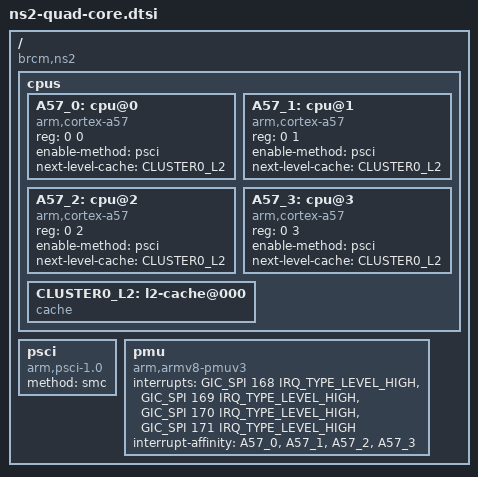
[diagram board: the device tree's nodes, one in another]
/*
 *  BSD LICENSE
 *
 *  Copyright (c) 2017 Broadcom.  All rights reserved.
 *
 *  Redistribution and use in source and binary forms, with or without
 *  modification, are permitted provided that the following conditions
 *  are met:
 *
 *    * Redistributions of source code must retain the above copyright
 *      notice, this list of conditions and the following disclaimer.
 *    * Redistributions in binary form must reproduce the above copyright
 *      notice, this list of conditions and the following disclaimer in
 *      the documentation and/or other materials provided with the
 *      distribution.
 *    * Neither the name of Broadcom Corporation nor the names of its
 *      contributors may be used to endorse or promote products derived
 *      from this software without specific prior written permission.
 *
 *  THIS SOFTWARE IS PROVIDED BY THE COPYRIGHT HOLDERS AND CONTRIBUTORS
 *  "AS IS" AND ANY EXPRESS OR IMPLIED WARRANTIES, INCLUDING, BUT NOT
 *  LIMITED TO, THE IMPLIED WARRANTIES OF MERCHANTABILITY AND FITNESS FOR
 *  A PARTICULAR PURPOSE ARE DISCLAIMED. IN NO EVENT SHALL THE COPYRIGHT
 *  OWNER OR CONTRIBUTORS BE LIABLE FOR ANY DIRECT, INDIRECT, INCIDENTAL,
 *  SPECIAL, EXEMPLARY, OR CONSEQUENTIAL DAMAGES (INCLUDING, BUT NOT
 *  LIMITED TO, PROCUREMENT OF SUBSTITUTE GOODS OR SERVICES; LOSS OF USE,
 *  DATA, OR PROFITS; OR BUSINESS INTERRUPTION) HOWEVER CAUSED AND ON ANY
 *  THEORY OF LIABILITY, WHETHER IN CONTRACT, STRICT LIABILITY, OR TORT
 *  (INCLUDING NEGLIGENCE OR OTHERWISE) ARISING IN ANY WAY OUT OF THE USE
 * OF THIS SOFTWARE, EVEN IF ADVISED OF THE POSSIBILITY OF SUCH DAMAGE.
 */
#include "ns2.dtsi"
/ {
	compatible = "brcm,ns2";
	cpus {
		#address-cells = <2>;
		#size-cells = <0>;

		A57_0: cpu@0 {
			device_type = "cpu";
			compatible = "arm,cortex-a57", "arm,armv8";
			reg = <0 0>;
			enable-method = "psci";
			next-level-cache = <&CLUSTER0_L2>;
		};

		A57_1: cpu@1 {
			device_type = "cpu";
			compatible = "arm,cortex-a57", "arm,armv8";
			reg = <0 1>;
			enable-method = "psci";
			next-level-cache = <&CLUSTER0_L2>;
		};

		A57_2: cpu@2 {
			device_type = "cpu";
			compatible = "arm,cortex-a57", "arm,armv8";
			reg = <0 2>;
			enable-method = "psci";
			next-level-cache = <&CLUSTER0_L2>;
		};

		A57_3: cpu@3 {
			device_type = "cpu";
			compatible = "arm,cortex-a57", "arm,armv8";
			reg = <0 3>;
			enable-method = "psci";
			next-level-cache = <&CLUSTER0_L2>;
		};

		CLUSTER0_L2: l2-cache@000 {
			compatible = "cache";
		};
	};

	psci {
		compatible = "arm,psci-1.0";
		method = "smc";
	};

	pmu {
		compatible = "arm,armv8-pmuv3";
		interrupts = <GIC_SPI 168 IRQ_TYPE_LEVEL_HIGH>,
		     <GIC_SPI 169 IRQ_TYPE_LEVEL_HIGH>,
		     <GIC_SPI 170 IRQ_TYPE_LEVEL_HIGH>,
		     <GIC_SPI 171 IRQ_TYPE_LEVEL_HIGH>;
		interrupt-affinity = <&A57_0>,
			     <&A57_1>,
			     <&A57_2>,
			     <&A57_3>;
	};
};
